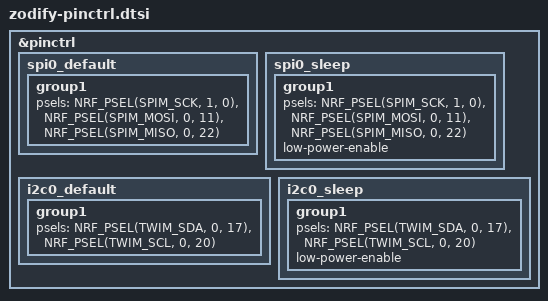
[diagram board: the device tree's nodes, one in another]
&pinctrl {
    /* configuration for spi0 device, default state */
    spi0_default: spi0_default {
        /* node name is arbitrary */
        group1 {
            /* main role: configure P0.01 as SPI clock, P0.02 as SPI MOSI, P0.03 as SPI MISO */
            psels = <NRF_PSEL(SPIM_SCK, 1, 0)>,
                    <NRF_PSEL(SPIM_MOSI, 0, 11)>,
                    <NRF_PSEL(SPIM_MISO, 0, 22)>;
        };
    };

    /* configuration for spi0 device, sleep state */
    spi0_sleep: spi0_sleep {
        group1 {
            /* main role: configure P0.01 as SPI clock, P0.02 as SPI MOSI, P0.03 as SPI MISO */
            psels = <NRF_PSEL(SPIM_SCK, 1, 0)>,
                    <NRF_PSEL(SPIM_MOSI, 0, 11)>,
                    <NRF_PSEL(SPIM_MISO, 0, 22)>;
            low-power-enable;
        };
    };
        /* configuration for i2c0 device, default state */
    i2c0_default: i2c0_default {
        group1 {
            psels = <NRF_PSEL(TWIM_SDA, 0, 17)>,
                <NRF_PSEL(TWIM_SCL, 0, 20)>;
        };
    };

    i2c0_sleep: i2c0_sleep {
        group1 {
            psels = <NRF_PSEL(TWIM_SDA, 0, 17)>,
                <NRF_PSEL(TWIM_SCL, 0, 20)>;
            low-power-enable;
        };
    };
};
